# Z20K14xM register map
Vendor: Zhixin Semiconductor; Series: Z20K14xM; File version: 0.1.0
CPU: CM4 r0p1, little endian, no MPU, FPU, 4 interrupt priority bits
Registers are 32-bit, read-write, reset 0x0 unless marked. A register's access mark holds for its fields unless they carry their own. Offsets are from the block's base; [hi:lo] are bit positions.

## SRMC
Base 0x4007E000
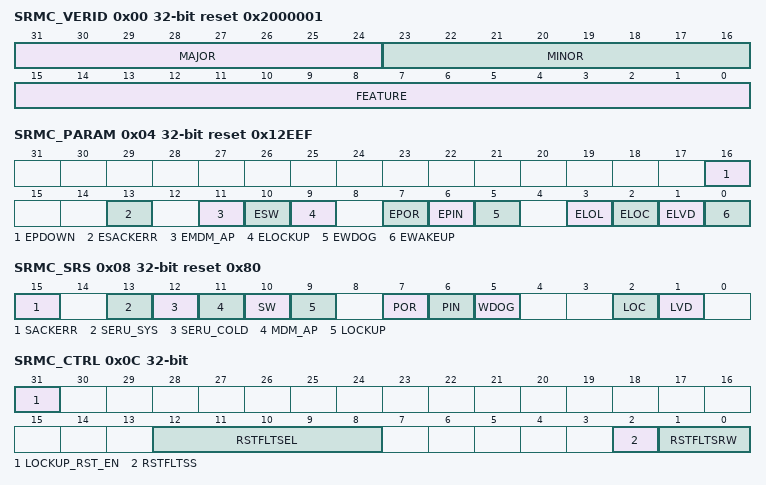
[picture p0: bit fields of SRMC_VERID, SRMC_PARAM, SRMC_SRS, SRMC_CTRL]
0x00 SRMC_VERID ro reset 0x2000001 — Version ID Register (SRMC_VERID)
  [31:24] MAJOR — Major Version Number
  [23:16] MINOR — Minor Version Number
  [15:0] FEATURE — Feature Number
0x04 SRMC_PARAM ro reset 0x12EEF — Parameter Register (SRMC_PARAM)
  [16] EPDOWN — Existence of PDOWN feature
  [13] ESACKERR — Existence of SRS[SACKERR] status indication feature
  [11] EMDM_AP — Existence of SRS[MDM_AP] status indication feature
  [10] ESW — Existence of SRS[SW] status indication feature
  [9] ELOCKUP — Existence of SRS[LOCKUP] status indication feature
  [7] EPOR — Existence of SRS[POR] status indication feature
  [6] EPIN — Existence of SRS[EPIN] status indication feature
  [5] EWDOG — Existence of SRS[EWOG] status indication feature
  [3] ELOL — Existence of SRS[LOL] status indication feature
  [2] ELOC — Existence of SRS[LOC] status indication feature
  [1] ELVD — Existence of SRS[LVD] status indication feature
  [0] EWAKEUP — Existence of SRS[WAKEUP] status indication feature
0x08 SRMC_SRS reset 0x80 — System Reset Status Register (SRMC_SRS)
  [15] SACKERR — Stop Acknowledge Error
  [13] SERU_SYS — SERU System Reset Request
  [12] SERU_COLD — SERU Cold Reset Request
  [11] MDM_AP — MDM-AP System Reset Request
  [10] SW — Software Reset
  [9] LOCKUP — LOCKUP Reset
  [7] POR — Power-On Reset
  [6] PIN — External Pin Reset
  [5] WDOG — WDOG Reset
  [2] LOC — Loss Of Clock Reset
  [1] LVD — Low Voltage Reset
0x0C SRMC_CTRL — Reset Control register (SRMC_CTRL)
  [31] LOCKUP_RST_EN — Core Lockup Reset enable
  [12:8] RSTFLTSEL — Reset Pin Filter Bus Clock Select
  [2] RSTFLTSS — Reset Pin Filter Select in Stop Mode
  [1:0] RSTFLTSRW — Reset Pin Filter Select in Run and Wait Modes
0x10 SRMC_MR ro — Reserved
0x14 SRMC_FM ro — Reserved
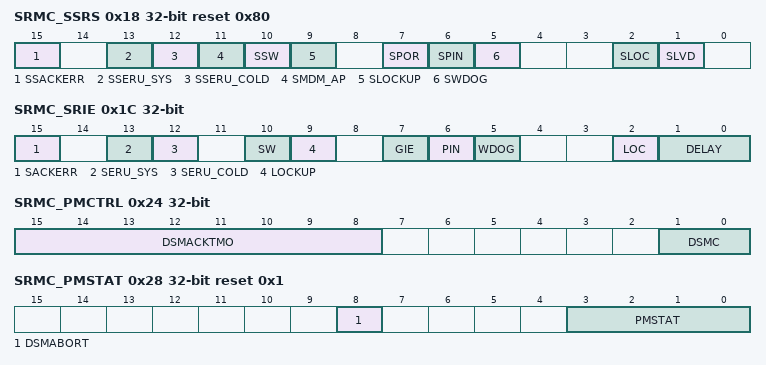
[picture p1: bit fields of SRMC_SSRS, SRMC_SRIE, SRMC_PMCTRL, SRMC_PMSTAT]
0x18 SRMC_SSRS ro reset 0x80 — Sticky System Reset Status Register (SRMC_SSRS)
  [15] SSACKERR — Sticky Stop Acknowledge Error
  [13] SSERU_SYS — Sticky SERU System Reset Request
  [12] SSERU_COLD — Sticky SERU Cold Reset Request
  [11] SMDM_AP — Sticky MDM-AP System Reset Request
  [10] SSW — Sticky Software Reset
  [9] SLOCKUP — Sticky Core Lock Up
  [7] SPOR — Sticky Power-On Reset
  [6] SPIN — Sticky external RESET pin Reset
  [5] SWDOG — Sticky watchdog timer timing out (WDOG)
  [2] SLOC — Sticky loss of external clock.
  [1] SLVD — Sticky low voltage reset
0x1C SRMC_SRIE — System Reset Interrupt Enable Register (SRMC_SRIE)
  [15] SACKERR — Stop Acknowledge Error Interrupt
  [13] SERU_SYS — SERU System Reset Request
  [12] SERU_COLD — SERU Cold Reset Request
  [10] SW — Software Reset Interrupt Enable
  [9] LOCKUP — Core Lockup Interrupt
  [7] GIE — Global Interrupt Enable
  [6] PIN — External Reset Pin Interrupt Enable
  [5] WDOG — Watchdog Interrupt Enable
  [2] LOC — Loss-of-Clock Interrupt Enable
  [1:0] DELAY — Maximum reset delay time
0x20 SRMC_PMPORT — Power Mode Protection register (SRMC_PMPROT)
  [0] APD — Allow Power down mode
0x24 SRMC_PMCTRL — Power Mode Control register (SRMC_PMCTRL)
  [15:8] DSMACKTMO — Deep Sleep Mode Acknowledge Time Out
  [1:0] DSMC — Deep Sleep Mode Configuration
0x28 SRMC_PMSTAT ro reset 0x1 — Power Mode Status register (SRMC_PMSTAT)
  [8] DSMABORT — Deep Sleep Mode Aborted
  [3:0] PMSTAT — PMSTAT Power Mode Status
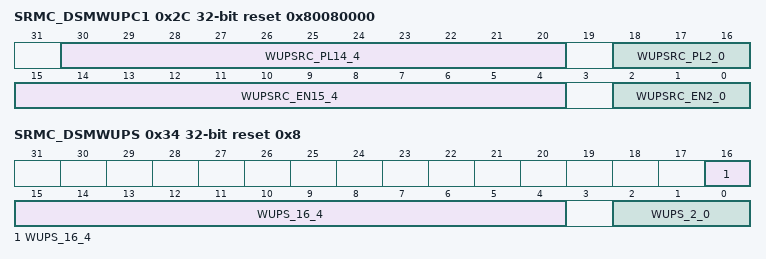
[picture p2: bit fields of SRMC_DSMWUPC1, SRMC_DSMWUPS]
0x2C SRMC_DSMWUPC1 reset 0x80080000 — DSM Wakeup Control Register (SRMC_DSMWUPC)
  [30:20] WUPSRC_PL14_4 — Wakeup Source Polarity
  [18:16] WUPSRC_PL2_0 — Wakeup Source Polarity
  [15:4] WUPSRC_EN15_4 — Wakeup Source Enable
  [2:0] WUPSRC_EN2_0 — Wakeup Source Enable
0x30 SRMC_DSMWUPC2 reset 0x10000 — DSM Wakeup Control Register (SRMC_DSMWUPC)
  [0] WUPSRC_EN16 — Wakeup Source Enable
0x34 SRMC_DSMWUPS reset 0x8 — DSM Wakeup Status Register (SRMC_DSMWUPS)
  [16:4] WUPS_16_4 — Wakeup Status
  [2:0] WUPS_2_0 — Wakeup Status
